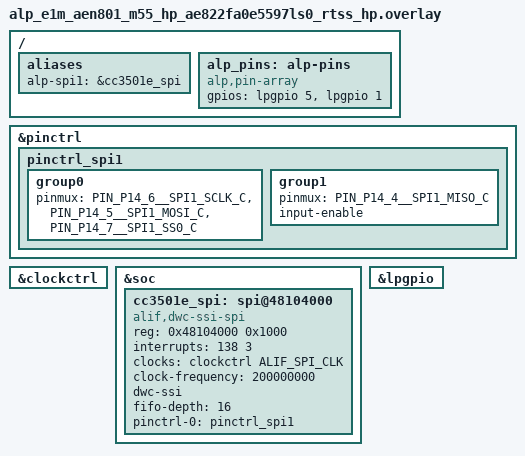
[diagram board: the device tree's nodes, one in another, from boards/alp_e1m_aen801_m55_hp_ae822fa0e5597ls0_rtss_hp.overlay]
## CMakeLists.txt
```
# SPDX-License-Identifier: Apache-2.0

cmake_minimum_required(VERSION 3.20)

find_package(Zephyr REQUIRED HINTS $ENV{ZEPHYR_BASE})
project(mqtt_telemetry LANGUAGES C)

target_sources(app PRIVATE src/main.c)
# Reusable SoM bring-up helper (cc3501e_bridge_bringup): the one-call CC3501E
# bridge init this app uses so alp_wifi_open() can bind to a ready bridge on
# E1M-AEN801 (#2112). Copyable template, same file as examples/aen/aen-cc3501e-*
# -- see src/cc3501e_bridge.h. Built unconditionally; alp_gpio_open()/alp_spi_open()
# fail fast (NULL, no matching backend) on native_sim, so this is a no-op there.
target_sources(app PRIVATE src/cc3501e_bridge.c)
```

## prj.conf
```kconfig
# SPDX-License-Identifier: Apache-2.0
#
# Empty-by-design Kconfig.  The effective build config is the
# overlay alp.conf emitted from board.yaml by `tan build`
# at build time (see scripts/gen_example_alp_conf.py) -- it turns the
# `iot: {wifi, tls}` toggles + `libraries: [mbedtls]` into the
# CONFIG_* the app needs (Wi-Fi, the MQTT client, mbedtls).
#
# mbedtls used to be forced OFF here and in a native_sim.conf, because
# the pinned mbedtls' ssl_misc.h uses `mbedtls_error_pair_t` with PSA
# crypto off and does not compile.  That is fixed at its root -- the SDK
# now turns mbedtls' PSA core on with mbedtls itself, see
# ALP_SDK_MBEDTLS_PSA_CRYPTO in zephyr/Kconfig.alp-libraries (#2173) --
# so every target, native_sim included, builds the same TLS-enabled
# configuration the SoM does.
```

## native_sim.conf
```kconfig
# SPDX-License-Identifier: Apache-2.0
#
# Native-sim Kconfig overlay for mqtt-telemetry.
#
# Loaded LAST via twister's `extra_args: EXTRA_CONF_FILE=...`
# (see ../testcase.yaml), so the settings here win over the
# alp.conf-emitted CONFIG_MBEDTLS=y that `iot.tls: true` +
# `libraries: [mbedtls]` pull into every mqtt-telemetry build.
#
# Why: Zephyr v4.4 ships mbedtls 3.6 + the new tf-psa-crypto split.
# The upstream library-internal header
# `mbedtls/library/ssl_misc.h` references `mbedtls_error_pair_t`
# before including the type's declaring header; every TU that
# compiles against the SSL portion of mbedtls fails with
# `unknown type name 'mbedtls_error_pair_t'`.  Full integration is
# a v0.6 (TF-M-on-HE + tf-psa-crypto wiring) work item.
#
# On native_sim there is no Wi-Fi radio and no MQTT-capable network
# stack, so alp_wifi_open()/alp_mqtt_open() resolve to the
# sw_fallback backend and return NULL/NOSUPPORT anyway; turning
# mbedtls off here keeps the framing build green while we exercise
# the <alp/iot.h> call sites + the graceful-degradation path.  Real
# AEN silicon (the CC3501E bridge + TF-M stack) is unaffected.
CONFIG_MBEDTLS=n
CONFIG_MBEDTLS_BUILTIN=n
CONFIG_MQTT_LIB_TLS=n
```

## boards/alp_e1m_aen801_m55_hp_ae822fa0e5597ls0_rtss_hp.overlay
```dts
/*
 * Copyright (c) 2026 Alp Lab AB
 * SPDX-License-Identifier: Apache-2.0
 *
 * E1M-AEN801 M55-HP overlay for mqtt-telemetry (#2363).  This example's only AEN
 * target is the M55-HP, but it shipped no board overlay, so the SPI1 /
 * CC3501E-bridge pads had no DT node or pinmux there and
 * cc3501e_bridge_bringup() (src/cc3501e_bridge.c, bus_id
 * CC3501E_BRIDGE_SPI_BUS_ID = 1, alp_pins WIFI_EN/NRST) returned
 * ALP_ERR_NOT_PRESENT_ON_THIS_SOC.
 *
 * Byte-for-byte the CC3501E bridge wiring of
 * examples/connectivity/iot-dashboard's M55-HP overlay (#2242), itself the
 * bridge subset of examples/peripheral-io/alp-console's bench-validated
 * M55-HE overlay -- the SoM-internal Alif<->CC3501E SPI1 link + the two
 * host-driven control nets, from metadata/e1m_modules/aen/inter-chip.tsv:
 *   SPI1.SCK P14_6  MOSI P14_5  MISO P14_4   WIFI_EN P15_5  NRST P15_1_FLEX
 * SPI1 @0x48104000 and lpgpio @0x42002000 come from the shared
 * zephyr/dts/alif/ensemble_e8_peripherals.dtsi the HP board dts also
 * includes, so the addresses are the same silicon the M55-HE overlays use.
 *
 * IRQ 138 is carried over from the M55-HE overlays; see their BENCH-TBD
 * comment.
 */
#include <zephyr/dt-bindings/pinctrl/alif-ensemble-pinctrl.h>
#include <zephyr/dt-bindings/gpio/gpio.h>

&pinctrl {
	/* SPI1 master (CC3501E bridge): SCK P14_6 / MOSI P14_5 / MISO P14_4 (alt-2, _C). */
	pinctrl_spi1: pinctrl_spi1 {
		group0 {
			/* SS0 (P14_7) is now peripheral-driven -- the dwc-ssi hardware chip-select,
			 * NOT the old GPIO bodge.  Push-pull output pad like SCLK/MOSI (no input-enable);
			 * the master asserts/deasserts SS0 per transfer (write_ser). */
			pinmux = <PIN_P14_6__SPI1_SCLK_C>, <PIN_P14_5__SPI1_MOSI_C>,
				 <PIN_P14_7__SPI1_SS0_C>;
		};
		group1 {
			pinmux = <PIN_P14_4__SPI1_MISO_C>;
			input-enable;
		};
	};
};

/* P14_7 (CS) is now muxed as SPI1_SS0_C in pinctrl_spi1 -- the dwc-ssi peripheral drives
 * it in hardware per transfer.  The old gpio14 GPIO-bodge controller node is removed: a
 * GPIO claim of P14_7 would fight the SS0 pinctrl mux. */

&clockctrl {
	status = "okay";
};

&soc {
	/* DWC_ssi SPI1 -- the on-SoM CC3501E inter-chip link (NOT the edge SPI0).
	 * 4-wire: SCLK/MOSI/MISO + the hardware SS0 chip-select (P14_7 = SPI1_SS0_C,
	 * declared in pinctrl_spi1 above); clock-frequency = 200 MHz, the real SSI
	 * functional clock (E8 HWRM), so spi_dw_alif skips the failing
	 * clock-control path. */
	cc3501e_spi: spi@48104000 {
		compatible = "alif,dwc-ssi-spi";
		#address-cells = <1>;
		#size-cells = <0>;
		reg = <0x48104000 0x1000>;
		interrupts = <138 3>;          /* BENCH-TBD: SPI1 IRQ */
		clocks = <&clockctrl ALIF_SPI_CLK>;
		/* Real SSI functional clock (E8 HWRM).  Was mis-set to 400000000 here,
		 * which is not a cosmetic error: spi_dw derives BAUDR =
		 * clock-frequency / freq_hz, so a doubled input clock doubles the
		 * divider and HALVES the real SCLK -- this node was running at
		 * 500 kHz while asking for 1 MHz.  Proven via BAUDR scaling and
		 * already corrected in the aen-cc3501e-* overlays. */
		clock-frequency = <200000000>;
		dwc-ssi;
		fifo-depth = <16>;
		/* `rx-delay` IS a real devicetree property
		 * (zephyr/dts/bindings/spi/alif,dwc-ssi-spi.yaml, int, default 0) --
		 * deliberately left UNSET here, not omitted because it doesn't exist.
		 * spi_dw_alif.c writes RX_SAMPLE_DLY (reg 0xF0, ssi_clk cycles at
		 * 200 MHz = 5 ns/cycle) from this property at BOTH init and PM resume
		 * (write_rxdly(dev, info->rx_delay)); spi_dw_configure() never touches
		 * the register outside those two paths. src/cc3501e_bridge.c pokes
		 * RX_SAMPLE_DLY itself once inside cc3501e_bridge_bringup(), after
		 * this node's init already ran, so the unset (0) property here does
		 * not matter today. The overwrite is LATENT, not live: only the
		 * `#if defined CONFIG_PM_DEVICE` resume path (spi_dw_alif.c) would
		 * re-write RX_SAMPLE_DLY from this property, and nothing in this app
		 * enables CONFIG_PM_DEVICE. CC3501E_BRIDGE_RX_SAMPLE_DLY is 4,
		 * silicon-tuned for ~25 MHz on E1M-AEN803 serial 2026W36-0002 --
		 * NOT 6 / ~14.3 MHz, an earlier measurement the header itself
		 * documents as stale and not comparable (see cc3501e_bridge.h's own
		 * correction). */
		pinctrl-0 = <&pinctrl_spi1>;
		pinctrl-names = "default";
		status = "okay";
	};
};

/* LP GPIO island: WIFI_EN (P15_5) + E_WIFI.NRST (P15_1_FLEX) as outputs. */
&lpgpio {
	status = "okay";
};

/ {
	aliases {
		alp-spi1 = &cc3501e_spi;   /* bus_id 1 in cc3501e_bridge_bringup() */
	};

	/* SoM-internal CC3501E control nets, in CC3501E_PIN_* index order. */
	alp_pins: alp-pins {
		compatible = "alp,pin-array";
		gpios = <&lpgpio 5 GPIO_ACTIVE_HIGH>,   /* [0] WIFI_EN     (P15_5)      */
			<&lpgpio 1 GPIO_ACTIVE_HIGH>;   /* [1] E_WIFI.NRST (P15_1_FLEX) */
	};
};
```

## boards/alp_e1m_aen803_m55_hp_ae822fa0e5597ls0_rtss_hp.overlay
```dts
/*
 * Copyright (c) 2026 Alp Lab AB
 * SPDX-License-Identifier: Apache-2.0
 *
 * E1M-AEN803 M55-HP overlay for mqtt-telemetry (#2363).  This example's only AEN
 * target is the M55-HP, but it shipped no board overlay, so the SPI1 /
 * CC3501E-bridge pads had no DT node or pinmux there and
 * cc3501e_bridge_bringup() (src/cc3501e_bridge.c, bus_id
 * CC3501E_BRIDGE_SPI_BUS_ID = 1, alp_pins WIFI_EN/NRST) returned
 * ALP_ERR_NOT_PRESENT_ON_THIS_SOC.
 *
 * Byte-for-byte the CC3501E bridge wiring of
 * examples/connectivity/iot-dashboard's M55-HP overlay (#2242), itself the
 * bridge subset of examples/peripheral-io/alp-console's bench-validated
 * M55-HE overlay -- the SoM-internal Alif<->CC3501E SPI1 link + the two
 * host-driven control nets, from metadata/e1m_modules/aen/inter-chip.tsv:
 *   SPI1.SCK P14_6  MOSI P14_5  MISO P14_4   WIFI_EN P15_5  NRST P15_1_FLEX
 * SPI1 @0x48104000 and lpgpio @0x42002000 come from the shared
 * zephyr/dts/alif/ensemble_e8_peripherals.dtsi the HP board dts also
 * includes, so the addresses are the same silicon the M55-HE overlays use.
 *
 * IRQ 138 is carried over from the M55-HE overlays; see their BENCH-TBD
 * comment.
 */
#include <zephyr/dt-bindings/pinctrl/alif-ensemble-pinctrl.h>
#include <zephyr/dt-bindings/gpio/gpio.h>

&pinctrl {
	/* SPI1 master (CC3501E bridge): SCK P14_6 / MOSI P14_5 / MISO P14_4 (alt-2, _C). */
	pinctrl_spi1: pinctrl_spi1 {
		group0 {
			/* SS0 (P14_7) is now peripheral-driven -- the dwc-ssi hardware chip-select,
			 * NOT the old GPIO bodge.  Push-pull output pad like SCLK/MOSI (no input-enable);
			 * the master asserts/deasserts SS0 per transfer (write_ser). */
			pinmux = <PIN_P14_6__SPI1_SCLK_C>, <PIN_P14_5__SPI1_MOSI_C>,
				 <PIN_P14_7__SPI1_SS0_C>;
		};
		group1 {
			pinmux = <PIN_P14_4__SPI1_MISO_C>;
			input-enable;
		};
	};
};

/* P14_7 (CS) is now muxed as SPI1_SS0_C in pinctrl_spi1 -- the dwc-ssi peripheral drives
 * it in hardware per transfer.  The old gpio14 GPIO-bodge controller node is removed: a
 * GPIO claim of P14_7 would fight the SS0 pinctrl mux. */

&clockctrl {
	status = "okay";
};

&soc {
	/* DWC_ssi SPI1 -- the on-SoM CC3501E inter-chip link (NOT the edge SPI0).
	 * 4-wire: SCLK/MOSI/MISO + the hardware SS0 chip-select (P14_7 = SPI1_SS0_C,
	 * declared in pinctrl_spi1 above); clock-frequency = 200 MHz, the real SSI
	 * functional clock (E8 HWRM), so spi_dw_alif skips the failing
	 * clock-control path. */
	cc3501e_spi: spi@48104000 {
		compatible = "alif,dwc-ssi-spi";
		#address-cells = <1>;
		#size-cells = <0>;
		reg = <0x48104000 0x1000>;
		interrupts = <138 3>;          /* BENCH-TBD: SPI1 IRQ */
		clocks = <&clockctrl ALIF_SPI_CLK>;
		/* Real SSI functional clock (E8 HWRM).  Was mis-set to 400000000 here,
		 * which is not a cosmetic error: spi_dw derives BAUDR =
		 * clock-frequency / freq_hz, so a doubled input clock doubles the
		 * divider and HALVES the real SCLK -- this node was running at
		 * 500 kHz while asking for 1 MHz.  Proven via BAUDR scaling and
		 * already corrected in the aen-cc3501e-* overlays. */
		clock-frequency = <200000000>;
		dwc-ssi;
		fifo-depth = <16>;
		/* `rx-delay` IS a real devicetree property
		 * (zephyr/dts/bindings/spi/alif,dwc-ssi-spi.yaml, int, default 0) --
		 * deliberately left UNSET here, not omitted because it doesn't exist.
		 * spi_dw_alif.c writes RX_SAMPLE_DLY (reg 0xF0, ssi_clk cycles at
		 * 200 MHz = 5 ns/cycle) from this property at BOTH init and PM resume
		 * (write_rxdly(dev, info->rx_delay)); spi_dw_configure() never touches
		 * the register outside those two paths. src/cc3501e_bridge.c pokes
		 * RX_SAMPLE_DLY itself once inside cc3501e_bridge_bringup(), after
		 * this node's init already ran, so the unset (0) property here does
		 * not matter today. The overwrite is LATENT, not live: only the
		 * `#if defined CONFIG_PM_DEVICE` resume path (spi_dw_alif.c) would
		 * re-write RX_SAMPLE_DLY from this property, and nothing in this app
		 * enables CONFIG_PM_DEVICE. CC3501E_BRIDGE_RX_SAMPLE_DLY is 4,
		 * silicon-tuned for ~25 MHz on E1M-AEN803 serial 2026W36-0002 --
		 * NOT 6 / ~14.3 MHz, an earlier measurement the header itself
		 * documents as stale and not comparable (see cc3501e_bridge.h's own
		 * correction). */
		pinctrl-0 = <&pinctrl_spi1>;
		pinctrl-names = "default";
		status = "okay";
	};
};

/* LP GPIO island: WIFI_EN (P15_5) + E_WIFI.NRST (P15_1_FLEX) as outputs. */
&lpgpio {
	status = "okay";
};

/ {
	aliases {
		alp-spi1 = &cc3501e_spi;   /* bus_id 1 in cc3501e_bridge_bringup() */
	};

	/* SoM-internal CC3501E control nets, in CC3501E_PIN_* index order. */
	alp_pins: alp-pins {
		compatible = "alp,pin-array";
		gpios = <&lpgpio 5 GPIO_ACTIVE_HIGH>,   /* [0] WIFI_EN     (P15_5)      */
			<&lpgpio 1 GPIO_ACTIVE_HIGH>;   /* [1] E_WIFI.NRST (P15_1_FLEX) */
	};
};
```

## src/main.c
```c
/*
 * Copyright 2026 Alp Lab AB
 * SPDX-License-Identifier: Apache-2.0
 *
 * mqtt-telemetry -- publish a sensor reading over MQTT/TLS.
 *
 * The "connected device" starting point.  It shows the whole
 * telemetry path a field device runs, all on the portable
 * <alp/iot.h> surface:
 *
 *   1. Bring the Wi-Fi station up + associate.   (alp_wifi_*)
 *   2. Open an mqtts:// (TLS) MQTT client.        (alp_mqtt_open)
 *   3. Connect to the broker.                     (alp_mqtt_connect)
 *   4. Publish a telemetry reading on a cadence.  (alp_mqtt_publish)
 *   5. Disconnect cleanly.                        (alp_mqtt_close)
 *
 * Transport (E1M-AEN801): the CC3501E Wi-Fi6+BLE coprocessor bridge
 * (docs/cc3501e-bridge.md), selected automatically by the AEN board
 * emit from `iot.wifi: true` -- the app never names it, it just
 * calls <alp/iot.h>.  The bridge is silicon-validated (2026-06-24);
 * this is a real transport, not a stub.
 *
 * Bridge bring-up (#2112): alp_wifi_open() only resolves to the CC3501E
 * backend once an application has attached a live bridge handle --
 * cc3501e_bridge_bringup() (src/cc3501e_bridge.c, the same copyable
 * template every examples/aen/aen-cc3501e-* app uses) does exactly that
 * before this app calls alp_wifi_open() below.  On native_sim the bring-up
 * fails fast (ALP_ERR_NOT_PRESENT_ON_THIS_SOC -- no SPI/GPIO backend
 * matches that SoC ref) and this app falls through to the same
 * NULL-with-NOT_READY framing path as before.
 *
 * The "sensor reading": to keep the focus on the transport, this
 * template publishes a synthetic metric (device uptime).  Swap
 * read_telemetry_value() for a real sensor read -- e.g. compose it
 * with the `sensor` template (examples/peripheral-io/i2c-master,
 * TMP112 over <alp/chips/tmp112.h>) -- and the publish path here is
 * unchanged.
 *
 * TLS status (preview): the mqtts:// path is configured through the
 * portable API (broker URI + pinned CA), but CONFIG_MBEDTLS is held
 * OFF in the build today -- Zephyr v4.4's mbedtls 3.6 has an
 * ssl_misc.h include-order bug; full tf-psa-crypto wiring is a v0.6
 * work item (see prj.conf / native_sim.conf).  Real AEN silicon
 * uses the TF-M stack.  This is why the catalog record is `preview`.
 *
 * What runs under native_sim (CI lane): there is no radio and no
 * MQTT-capable net stack, so alp_wifi_open()/alp_mqtt_open() return
 * NULL -- ALP_ERR_NOT_READY when a backend registered but its device
 * isn't up, or ALP_ERR_NOSUPPORT when no backend is linked at all;
 * both are the documented <alp/iot.h> NULL contract.  The app
 * detects that, prints the telemetry payloads it WOULD publish (so
 * the framing is CI-observable), and exits on the `[mqtt] done`
 * marker.
 *
 * What runs on AEN HiL: real association through the CC3501E, real
 * MQTT publish to the broker; the same source, no #ifdef in the
 * telemetry logic.
 */

#include <stdint.h>
#include <stdio.h>
#include <string.h>

#include "alp/iot.h"
#include "cc3501e_bridge.h" /* cc3501e_bridge_bringup() -- the SoM bring-up template, #2112 */

/* Broker + topic identity.  In a real fleet these come from the
 * device's provisioning step; hardcoded here as documentation.
 * mqtts:// selects the TLS path (see the TLS config below). */
#define MQTT_BROKER_URI "mqtts://broker.example.alplab.ai:8883"
#define MQTT_CLIENT_ID  "e1m-aen801-demo"
#define MQTT_TOPIC      "alp/telemetry/e1m-aen801"

/* Pin the broker's CA bundle.  NULL would fall back to the OS
 * default trust store; a real deployment should pin a known-good
 * CA, so we name the path a customer would provision. */
#define MQTT_CA_FILE "/etc/ssl/certs/alp-broker-ca.pem"

/* Wi-Fi credentials.  On real silicon these come from the EEPROM
 * factory manifest or a provisioning blob so one binary serves a
 * whole fleet; hardcoded for the demo. */
#define WIFI_SSID "alp-demo-ap"
#define WIFI_PSK  "changeme-in-provisioning"

/* Publish a bounded number of readings so the native_sim run
 * terminates and the twister harness latches.  Real firmware would
 * publish forever on a timer. */
#define PUBLISH_COUNT    3u
#define PUBLISH_PERIOD_S 5u

/* Handshake budgets.
 *
 * WIFI_CONNECT_TIMEOUT_MS: on E1M-AEN801 with the CC3501E bridge attached,
 * alp_wifi_connect() routes to the CC3501E backend
 * (src/backends/wifi/cc3501e.c), and the bridge's own worst case for one STA
 * connect is 10s Wlan_RoleUp + 30s L2 association + a 30s DHCP-lease poll
 * (hal/ti/cc3501e_hw_ti_wifi.c) = 70s. On other Wi-Fi backends this value is
 * only an upper bound, not a derived worst case. */
#define WIFI_CONNECT_TIMEOUT_MS 75000u
#define MQTT_CONNECT_TIMEOUT_MS 10000u

/* Read one telemetry value.
 *
 * PLACEHOLDER: returns a synthetic uptime-seconds counter so the
 * template stays chip-free and focused on the transport.  On real
 * hardware, replace the body with a sensor read -- e.g. a TMP112
 * temperature via <alp/chips/tmp112.h> (see the `sensor` template)
 * -- and return that value.  The publish path below does not change. */
static uint32_t read_telemetry_value(uint32_t sample_index)
{
	/* Synthetic: seconds of "uptime" at this sample's cadence.
	 * Deterministic so the native_sim framing output is stable. */
	return sample_index * PUBLISH_PERIOD_S;
}

/* Format a telemetry sample as a compact JSON payload.  Returns the
 * byte length written (excluding the NUL), or 0 on truncation. */
static size_t build_payload(char *buf, size_t cap, uint32_t value)
{
	int n = snprintf(buf,
	                 cap,
	                 "{\"device\":\"%s\",\"metric\":\"uptime_s\",\"value\":%u}",
	                 MQTT_CLIENT_ID,
	                 value);
	if (n < 0 || (size_t)n >= cap) {
		return 0u; /* truncated -- caller skips the publish */
	}
	return (size_t)n;
}

/* Bring the Wi-Fi station up + associate.  Returns an open handle
 * on success, or NULL (with the reason logged) when there is no
 * Wi-Fi backend on this build -- the native_sim / sw_fallback path. */
static alp_wifi_t *telemetry_wifi_up(void)
{
	/* STATIC, not a local -- cc3501e_t embeds several
	 * ALP_CC3501E_MAX_PAYLOAD scratch buffers; see cc3501e_bridge.h. */
	static cc3501e_t bridge = { 0 };

	printf("[mqtt] wifi: bridge bring-up\n");
	alp_status_t bridge_rc = cc3501e_bridge_bringup(&bridge);
	printf("[mqtt] wifi: cc3501e_bridge_bringup -> %s\n", alp_status_name(bridge_rc));

	printf("[mqtt] wifi: opening station\n");
	alp_wifi_t *w = alp_wifi_open();
	if (w == NULL) {
		/* NOT_READY on native_sim (a Wi-Fi backend registered but no
		 * device is up) or NOSUPPORT when no Wi-Fi backend is linked;
		 * on HiL, NOT_READY before the CC3501E bridge has probed. */
		printf("[mqtt] wifi: alp_wifi_open -> NULL (%s)\n", alp_status_name(alp_last_error()));
		return NULL;
	}
	const alp_wifi_credentials_t creds = {
		.ssid = WIFI_SSID,
		.psk  = WIFI_PSK,
	};
	alp_status_t s = alp_wifi_connect(w, &creds, WIFI_CONNECT_TIMEOUT_MS);
	if (s != ALP_OK) {
		printf("[mqtt] wifi: connect -> %s\n", alp_status_name(s));
		alp_wifi_close(w);
		return NULL;
	}
	printf("[mqtt] wifi: associated to \"%s\"\n", WIFI_SSID);
	return w;
}

/* Open + connect the TLS MQTT client.  Returns an open handle, or
 * NULL when there is no MQTT backend on this build. */
static alp_mqtt_t *telemetry_mqtt_up(void)
{
	printf("[mqtt] broker: opening %s (TLS, CA pinned)\n", MQTT_BROKER_URI);

	/* Pin the broker CA for the mqtts:// handshake.  insecure
	 * stays false -- a starter must not teach cert-skipping. */
	static const alp_mqtt_tls_config_t tls = {
		.ca_file  = MQTT_CA_FILE,
		.insecure = false,
	};
	alp_mqtt_config_t cfg = ALP_MQTT_CONFIG_DEFAULT(MQTT_BROKER_URI);
	cfg.client_id         = MQTT_CLIENT_ID;
	cfg.tls               = &tls;

	alp_mqtt_t *m = alp_mqtt_open(&cfg);
	if (m == NULL) {
		printf("[mqtt] broker: alp_mqtt_open -> NULL (%s)\n", alp_status_name(alp_last_error()));
		return NULL;
	}
	alp_status_t s = alp_mqtt_connect(m, MQTT_CONNECT_TIMEOUT_MS);
	if (s != ALP_OK) {
		printf("[mqtt] broker: connect -> %s\n", alp_status_name(s));
		alp_mqtt_close(m);
		return NULL;
	}
	printf("[mqtt] broker: connected\n");
	return m;
}

/* Publish PUBLISH_COUNT readings on the live client. */
static void telemetry_publish_loop(alp_mqtt_t *m)
{
	for (uint32_t i = 0; i < PUBLISH_COUNT; i++) {
		char   payload[96];
		size_t len = build_payload(payload, sizeof(payload), read_telemetry_value(i));
		if (len == 0u) {
			printf("[mqtt] publish %u: payload truncated -- skipped\n", i);
			continue;
		}
		alp_status_t s =
		    alp_mqtt_publish(m, MQTT_TOPIC, (const uint8_t *)payload, len, ALP_MQTT_QOS_1, false);
		printf("[mqtt] publish %u -> %s: %s\n", i, alp_status_name(s), payload);

		/* Pace the publishes -- a real telemetry device sends on a
		 * timer, not in a tight loop.  alp_delay_ms is portable
		 * (<alp/peripheral.h>, reached via <alp/iot.h>). */
		if (i + 1u < PUBLISH_COUNT) {
			alp_delay_ms(PUBLISH_PERIOD_S * 1000u);
		}
	}
}

/* native_sim / no-backend path: there's no live client, but print
 * the payloads the app WOULD publish so the framing is observable
 * in CI (and so a customer sees the message shape without a broker). */
static void telemetry_print_framing(void)
{
	printf("[mqtt] no transport on this build -- printing framing only\n");
	for (uint32_t i = 0; i < PUBLISH_COUNT; i++) {
		char   payload[96];
		size_t len = build_payload(payload, sizeof(payload), read_telemetry_value(i));
		if (len == 0u) {
			continue;
		}
		printf("[mqtt] would publish to %s: %s\n", MQTT_TOPIC, payload);
	}
}

int main(void)
{
	/* Bring up the SDK runtime before anything else. */
	(void)alp_init();

	printf("[mqtt] alp-sdk mqtt-telemetry demo (publish over MQTT/TLS)\n");
	printf("[mqtt] transport: CC3501E Wi-Fi bridge (E1M-AEN801)\n");

	alp_wifi_t *w = telemetry_wifi_up();
	if (w != NULL) {
		alp_mqtt_t *m = telemetry_mqtt_up();
		if (m != NULL) {
			telemetry_publish_loop(m);
			alp_mqtt_close(m);
		}
		alp_wifi_disconnect(w);
		alp_wifi_close(w);
	} else {
		/* No Wi-Fi backend (native_sim): show the framing so the
		 * run is still meaningful + the harness has a marker. */
		telemetry_print_framing();
	}

	printf("[mqtt] done\n");
	return 0;
}
```

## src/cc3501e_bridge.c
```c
/*
 * SPDX-License-Identifier: Apache-2.0
 * Copyright 2026 Alp Lab AB
 *
 * E1M-AEN SoM CC3501E bridge bring-up helper -- see cc3501e_bridge.h.
 *
 * The final reset is warm-aware.  cc3501e_reset() drops WIFI_EN for 50 ms, a
 * supply cold cycle; on a CC3501E that is already running (an activated unit with
 * vendor_sbl_container_enable=1 may then never relaunch) that must not happen on a
 * mere re-run or warm reset of the application.  So when WIFI_EN already reads high
 * AND the chip answers a PING the bring-up resets through nRESET only
 * (cc3501e_hard_reset()), and uses cc3501e_reset() only from WIFI_EN low or, as a
 * last resort, from a chip that stays silent through an nRESET-only reset.  WIFI_EN
 * reading high alone is not trusted: a pull-up would make every power-on look warm
 * (whether the module has one is an open question, issue #2797).
 */

#include "cc3501e_bridge.h"

#include <stdio.h>

#if defined(CONFIG_SOC_AE822FA0E5597LS0_RTSS_HE) || defined(CONFIG_SOC_AE822FA0E5597LS0_RTSS_HP)
#include <zephyr/arch/cpu.h>
#include <zephyr/devicetree.h>
#include <zephyr/sys/sys_io.h>
/*
 * AEN LP-pad mux (Alif Ensemble E8, both M55-HE and M55-HP cores).  WIFI_EN
 * (P15_5) and nRESET (P15_1) are on the Alif LP-GPIO island, bound by the
 * generic snps,designware-gpio driver which does NOT apply Alif pinctrl --
 * so the LP pads stay un-muxed and their output drivers OFF (confirmed on
 * silicon on M55-HE: WIFI_EN never powers the CC3501E until these regs are
 * set).  0x23 = the Alif GPIO-output pad config (driver + read-enable +
 * drive strength).  TODO: drop this raw poke once the Alif GPIO backend
 * muxes the LP island via pinctrl.
 *
 * ALIF_LPGPIO_PADCTRL_BASE (0x42007000) is not an M55-HE-local address: the
 * shared upstream `pin-controller@1a603000` node (ensemble_common.dtsi,
 * included by both cores' SoC dtsi) declares this exact window as its
 * second `reg` range, and `alp_e1m_aen801_m55_hp-pinctrl.dtsi` already
 * muxes a different LP-GPIO pad (P15_0, RTC_ALARM) from the M55-HP pinctrl
 * driver through it, so the poke below is equally applicable on M55-HP.
 * Running it on M55-HP is NOT bench-proven -- only running it on M55-HE has
 * been confirmed on silicon.
 */
#define ALIF_LPGPIO_PADCTRL_BASE 0x42007000u
#define ALIF_PAD_GPIO_OUTPUT     0x23u
/* Latch WIFI_EN (P15_5) HIGH in the port's data register while the pad is still an
 * INPUT.  Switching the direction afterwards then drives the already-high level; the
 * other order (direction first, value second -- what gpio_dw's configure does even
 * with an init flag) drives whatever DR holds, and with DR bit 5 = 0 that glitches
 * the supply of a running chip low.  DR is written directly (read-modify-write, the
 * same access gpio_dw's port_set_bits_raw makes) so this template stays on the
 * portable <alp/*.h> surface: SWPORTA_DR is offset 0x00 of the DesignWare GPIO block
 * (zephyr drivers/gpio/gpio_dw_registers.h), the block base is the `lpgpio` node's
 * reg, and the LP-GPIO clock is already on because alp_gpio_open() opened the pin. */
#define DW_GPIO_SWPORTA_DR 0x00u
static void aen_wifi_en_latch_high(void)
{
	const mem_addr_t dr = DT_REG_ADDR(DT_NODELABEL(lpgpio)) + DW_GPIO_SWPORTA_DR;

	sys_write32(sys_read32(dr) | (1u << 5), dr);
}

static void aen_lp_pads_enable_output(void)
{
	sys_write32(ALIF_PAD_GPIO_OUTPUT, ALIF_LPGPIO_PADCTRL_BASE + 5u * 4u); /* P15_5 WIFI_EN */
	sys_write32(ALIF_PAD_GPIO_OUTPUT, ALIF_LPGPIO_PADCTRL_BASE + 1u * 4u); /* P15_1 nRESET  */
}
#else
static inline void aen_lp_pads_enable_output(void)
{
}
static inline void aen_wifi_en_latch_high(void)
{
}
#endif

alp_status_t cc3501e_bridge_bringup(cc3501e_t *fw)
{
	if (fw == NULL) {
		return ALP_ERR_INVAL;
	}

	/* 1. Control pins: WIFI_EN (supply gate) + nRESET.  These are Alif LP-GPIO
	 *    pads, not E1M edge pads -- the SoM owns them. */
	alp_gpio_t *wifi_en = alp_gpio_open(CC3501E_BRIDGE_PIN_WIFI_EN);
	alp_gpio_t *nrst    = alp_gpio_open(CC3501E_BRIDGE_PIN_NRST);
	if (wifi_en == NULL || nrst == NULL) {
		if (wifi_en != NULL) {
			alp_gpio_close(wifi_en);
		}
		if (nrst != NULL) {
			alp_gpio_close(nrst);
		}
		return ALP_ERR_NOT_PRESENT_ON_THIS_SOC;
	}
	aen_lp_pads_enable_output();
	/* Sample the supply gate BEFORE touching its direction.  High is only a HINT
	 * that the chip may be powered -- an external pull-up on WIFI_EN would make every
	 * power-on read high (whether the module has one is an OPEN QUESTION; the
	 * netlist has not been checked), so the decision below also needs a PING. */
	bool wifi_was_high = false;
	(void)alp_gpio_read(wifi_en, &wifi_was_high);
	if (wifi_was_high) {
		/* Latch the level in DR first so the direction change cannot glitch it low. */
		aen_wifi_en_latch_high();
	}
	(void)alp_gpio_configure(wifi_en, ALP_GPIO_OUTPUT, ALP_GPIO_PULL_NONE);
	(void)alp_gpio_configure(nrst, ALP_GPIO_OUTPUT, ALP_GPIO_PULL_NONE);

	/* 2. Inter-chip SPI (Alif = master).  CS is the dwc-ssi hardware SS0
	 *    muxed on P14_7; the app passes ALP_SPI_NO_CS so no software GPIO CS
	 *    is installed and the SPI controller drives SS0 per transfer.  Mode 0
	 *    matches the CC3501E vendor image frameFormat. */
	alp_spi_t *spi = alp_spi_open(&(alp_spi_config_t){
	    .bus_id        = CC3501E_BRIDGE_SPI_BUS_ID,
	    .freq_hz       = CC3501E_BRIDGE_SPI_FREQ_HZ,
	    .mode          = ALP_SPI_MODE_0,
	    .bits_per_word = 8u,
	    .cs_pin_id     = ALP_SPI_NO_CS,
	});
	if (spi == NULL) {
		alp_gpio_close(wifi_en);
		alp_gpio_close(nrst);
		return ALP_ERR_NOT_PRESENT_ON_THIS_SOC;
	}

#if CC3501E_BRIDGE_RX_SAMPLE_DLY > 0
	/* Raise the SCLK past 1 MHz: the DW SSI RX_SAMPLE_DLY register (0xf0) delays
	 * the MISO capture point by N ssi_clk cycles to cover the on-SoM trace + crossed
	 * data round-trip.  Zephyr spi_dw never writes it (leaves 0), so without this
	 * >1 MHz mis-samples MISO (cold reqhdr_rx=0xFFFFFFFF).  Written with SSI disabled
	 * (SSIENR=0); persists across the driver's per-transfer configure.  Value is
	 * silicon-tuned -- sweep CC3501E_BRIDGE_RX_SAMPLE_DLY at the target SCLK.
	 *
	 * SWEEP TRAP -- read before setting the constant to 0: the `#if > 0` above
	 * compiles this block out, so 0 does not mean "no delay", it means the SPI
	 * node's `rx-delay` devicetree value is left in place.  aen-cc3501e-bringup
	 * and aen-evk-demo declare rx-delay = <2>, so a naive N=0 sweep point on
	 * those two silently measures 2.  Read 0x481040F0 back to see what the link
	 * is actually running at. */
	{
		volatile uint32_t *ssienr =
		    (volatile uint32_t *)(uintptr_t)(CC3501E_BRIDGE_SPI1_BASE + 0x08u);
		volatile uint32_t *rsd = (volatile uint32_t *)(uintptr_t)(CC3501E_BRIDGE_SPI1_BASE + 0xf0u);
		uint32_t           en  = *ssienr;
		*ssienr                = 0u;
		*rsd                   = (uint32_t)CC3501E_BRIDGE_RX_SAMPLE_DLY;
		*ssienr                = en;
	}
#endif

	/* 3. Bind the bus + control pins; attach the GPIO proxy (proxied E1M IOs then
	 *    route over the bridge); run the power + reset sequence (TI SWRU626 + the
	 *    Puya cold-boot hard-reset workaround).  Leaves WIFI_EN HIGH. */
	(void)cc3501e_init(fw, spi);
	fw->enable_pin = wifi_en;
	fw->reset_pin  = nrst;
	/* READY (CC35 GPIO17) is NOT wired here by default on this R2 module --
	 * see chips/cc3501e/cc3501e_core.c's cc3501e_reply_gate() comment for the
	 * pin-routing fact, the bench evidence, and how a board that genuinely
	 * wires it can opt back in via fw->ready_pin. */
#ifdef CONFIG_ALP_SDK_GPIO_CC3501E_PROXY
	(void)alp_gpio_cc3501e_attach(fw);
#endif
#ifdef CONFIG_ALP_SDK_WIFI_CC3501E
	(void)alp_wifi_cc3501e_attach(fw);
#endif
#ifdef CONFIG_ALP_SDK_BLE_CC3501E
	(void)alp_ble_cc3501e_attach(fw);
#endif
	/* One line naming the path taken, so a log shows whether the supply was cycled. */
	if (!wifi_was_high) {
		printf("[cc3501e_bridge] WIFI_EN low: cold power-up (cc3501e_reset)\n");
		return cc3501e_reset(fw); /* supply low: the full cold-boot sequence */
	}
	/* WIFI_EN reads high.  Warm = the chip ANSWERS a PING; a pull-up alone proves
	 * nothing.  Warm: nRESET only, never a WIFI_EN toggle. */
	if (cc3501e_ping(fw) == ALP_OK) {
		printf("[cc3501e_bridge] WIFI_EN high, PING ok: warm, nRESET only\n");
		return cc3501e_hard_reset(fw);
	}
	/* High but silent: powered-and-hung, or unpowered behind a pull-up.  Try the
	 * nRESET-only reset first (safe for a powered chip); only if the chip still does
	 * not answer is the supply cycled -- the last resort, taken from a chip that is
	 * already unresponsive. */
	if (cc3501e_hard_reset(fw) == ALP_OK && cc3501e_ping(fw) == ALP_OK) {
		printf("[cc3501e_bridge] WIFI_EN high, silent: recovered by nRESET only\n");
		return ALP_OK;
	}
	printf("[cc3501e_bridge] WIFI_EN high, silent after nRESET: supply cycle (cc3501e_reset)\n");
	return cc3501e_reset(fw);
}
```
